AUTOSAR XML (schema 4-2-1)
package /ComponentTypes
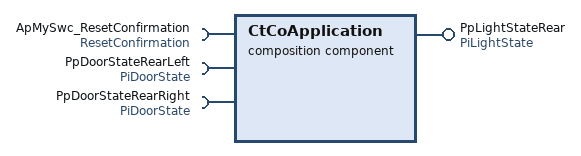
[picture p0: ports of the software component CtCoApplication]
  composition sw component type CtCoApplication
    provide port PpLightStateRear: nonqueued-sender-com-spec=data-element=DeLightState, provided-interface=PiLightState
    require port ApMySwc_ResetConfirmation: required-interface=ResetConfirmation
    require port PpDoorStateRearLeft: nonqueued-receiver-com-spec{data-element=DeDoorState, filter=data-filter-type=ALWAYS}, required-interface=PiDoorState
    require port PpDoorStateRearRight: nonqueued-receiver-com-spec{data-element=DeDoorState, filter=data-filter-type=ALWAYS}, required-interface=PiDoorState
    6 x component:
      CpApMySwc: type=CtApMySwc
      CpSaDoorFrontLeft: type=CtSaDoor
      CpSaDoorFrontRight: type=CtSaDoor
      CpSaInteriorLightFront: type=CtSaInteriorLight
      CpSaLightDimControl: type=CtSaLightDimControl
      ctNvApp: type=ctNvApp
    connect CpApMySwc.PpLightStateFront -> CpSaInteriorLightFront.PpLightState
    connect CpSaDoorFrontLeft.PpDoorState -> CpApMySwc.PpDoorStateFrontLeft
    connect CpSaDoorFrontRight.PpDoorState -> CpApMySwc.PpDoorStateFrontRight
    connect CpSaLightDimControl.PpLightDimControl -> CpApMySwc.PpLightDimControl
    connect CpSaLightDimControl.piAdcValue -> ctNvApp.piAdcValue
    delegate CpApMySwc.ApMySwc_ResetConfirmation <-> outer port ApMySwc_ResetConfirmation
    delegate CpApMySwc.PpDoorStateRearLeft <-> outer port PpDoorStateRearLeft
    delegate CpApMySwc.PpDoorStateRearRight <-> outer port PpDoorStateRearRight
    delegate CpApMySwc.PpLightStateRear <-> outer port PpLightStateRear
